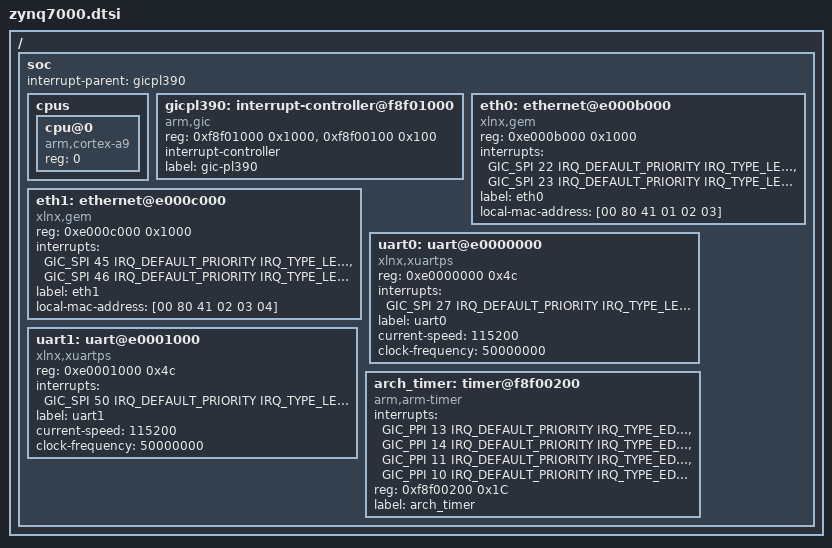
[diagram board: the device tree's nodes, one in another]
/*
 * Copyright (c) 2019 Lexmark International, Inc.
 * Copyright (c) 2020 Immo Birnbaum
 * SPDX-License-Identifier: Apache-2.0
 */

#include <mem.h>
#include <arm/armv7-a.dtsi>
#include <dt-bindings/interrupt-controller/arm-gic.h>

/ {
    soc {
        interrupt-parent = <&gicpl390>;

        cpus {
            #address-cells = <1>;
            #size-cells = <0>;

            cpu@0 {
                device_type = "cpu";
                compatible = "arm,cortex-a9";
                reg = <0>;
            };
        };

        gicpl390: interrupt-controller@f8f01000 {
            compatible = "arm,gic";
            reg = <0xf8f01000 0x1000>,
                  <0xf8f00100 0x100>;
            interrupt-controller;
            #interrupt-cells = <4>;
            label = "gic-pl390";
            status = "okay";
        };

        eth0: ethernet@e000b000 {
            compatible = "xlnx,gem";
            reg = <0xe000b000 0x1000>;
            status = "okay";
            interrupts = <GIC_SPI 22 IRQ_DEFAULT_PRIORITY IRQ_TYPE_LEVEL>,
                         <GIC_SPI 23 IRQ_DEFAULT_PRIORITY IRQ_TYPE_LEVEL>;
            interrupt-names = "irq_0", "irq_1";
            label = "eth0";
            local-mac-address = [00 80 41 01 02 03];
        };

        eth1: ethernet@e000c000 {
            compatible = "xlnx,gem";
            reg = <0xe000c000 0x1000>;
            status = "okay";
            interrupts = <GIC_SPI 45 IRQ_DEFAULT_PRIORITY IRQ_TYPE_LEVEL>,
                         <GIC_SPI 46 IRQ_DEFAULT_PRIORITY IRQ_TYPE_LEVEL>;
            interrupt-names = "irq_0", "irq_1";
            label = "eth1";
            local-mac-address = [00 80 41 02 03 04];
        };

        uart0: uart@e0000000 {
            compatible = "xlnx,xuartps";
            reg = <0xe0000000 0x4c>;
            status = "okay";
            interrupts = <GIC_SPI 27 IRQ_DEFAULT_PRIORITY IRQ_TYPE_LEVEL>;
            interrupt-names = "irq_0";
            label = "uart0";
            current-speed = <115200>;
            clock-frequency = <50000000>;
        };

        uart1: uart@e0001000 {
            compatible = "xlnx,xuartps";
            reg = <0xe0001000 0x4c>;
            status = "okay";
            interrupts = <GIC_SPI 50 IRQ_DEFAULT_PRIORITY IRQ_TYPE_LEVEL>;
            interrupt-names = "irq_0";
            label = "uart1";
            current-speed = <115200>;
            clock-frequency = <50000000>;
        };

        arch_timer: timer@f8f00200 {
            compatible = "arm,arm-timer";
	    status = "okay";
            interrupt-names = "irq_0", "irq_1", "irq_2", "irq_3";
            interrupts = <GIC_PPI 13 IRQ_DEFAULT_PRIORITY IRQ_TYPE_EDGE>,
                         <GIC_PPI 14 IRQ_DEFAULT_PRIORITY IRQ_TYPE_EDGE>,
                         <GIC_PPI 11 IRQ_DEFAULT_PRIORITY IRQ_TYPE_EDGE>,
                         <GIC_PPI 10 IRQ_DEFAULT_PRIORITY IRQ_TYPE_EDGE>;
            reg = <0xf8f00200 0x1C>;
            label = "arch_timer";
	};
    };
};
